# ATSAMRH707F18A register map
Vendor: Microchip Technology; Series: SAMRH707; File version: 0
CPU: CM7 r1p1, little endian, MPU, FPU, double-precision FPU, I-cache, D-cache, ITCM, DTCM, 3 interrupt priority bits, 69 interrupts
Registers are 32-bit, read-write, reset 0x0 unless marked. A register's access mark holds for its fields unless they carry their own. Offsets are from the block's base; [hi:lo] are bit positions; {n}, {i} and the like mark numbered series.

## CoreDebug
Base 0xE000EDF0
0x00 DHCSR — Debug Halting Control and Status Register
  [25] S_RESET_ST ro — Reset Status
  [24] S_RETIRE_ST ro — Retire Status
  [19] S_LOCKUP ro — Locked up status
  [18] S_SLEEP ro — Sleep status
  [17] S_HALT ro — Debug state status
  [16] S_REGRDY ro — Transfer complete flag
  [31:16] DBGKEY wo — Debug key, must write 0xA05F to enable writes
  [5] C_SNAPSTALL — Allow imprecise entry to Debug state
  [3] C_MASKINTS — Mask PendSV, SysTick and external configurable interrupts
  [2] C_STEP — Processor step bit
  [1] C_HALT — Processor halt bit
  [0] C_DEBUGEN — Halting debug enable bit
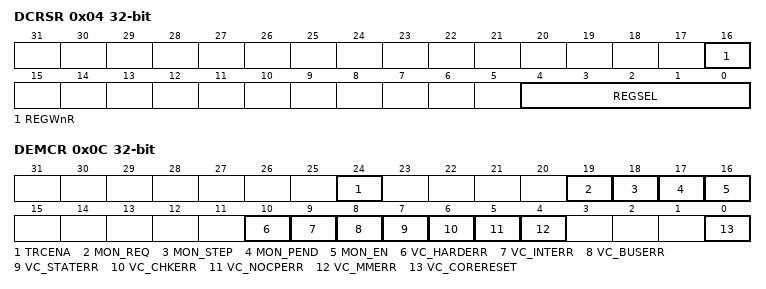
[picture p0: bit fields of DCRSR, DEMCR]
0x04 DCRSR wo — Debug Core Register Selector Register
  [16] REGWnR — Specifies the access type for the transfer
  [4:0] REGSEL — Specifies the Arm core register, special-purpose register, or Floating-point Extension register, to transfer
0x08 DCRDR — Debug Core Register Data Register
  [31:0] DBGTMP — Data temporary cache
0x0C DEMCR — Debug Exception and Monitor Control Register
  [24] TRCENA — Global enable for all DWT and ITM features
  [19] MON_REQ — DebugMonitor semaphore bit
  [18] MON_STEP — Enable DebugMonitor stepping
  [17] MON_PEND — Set DebugMonitor exception pending
  [16] MON_EN — Enable DebugMonitor exception
  [10] VC_HARDERR — HardFault exception catch
  [9] VC_INTERR — Interrupt/exception service error catch
  [8] VC_BUSERR — BusFault exception catch
  [7] VC_STATERR — State error catch
  [6] VC_CHKERR — Checking error catch
  [5] VC_NOCPERR — Coprocessor access error catch
  [4] VC_MMERR — MemManage exception catch
  [0] VC_CORERESET — Reset Vector Catch

## ETM — Embedded Trace Macrocell
Base 0xE0041000
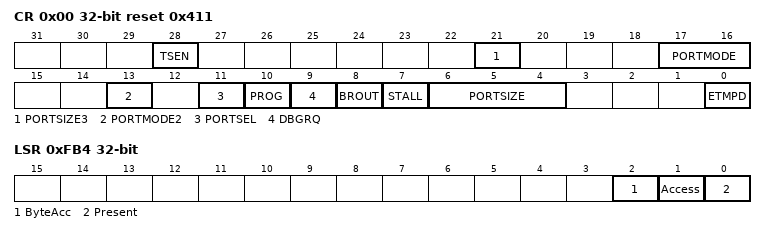
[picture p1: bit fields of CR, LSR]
0x00 CR reset 0x411 — ETM Main Control Register
  [28] TSEN — TimeStamp Enable
  [21] PORTSIZE3 — Port Size bit 3
  [17:16] PORTMODE — Port Mode bits 1:0
  [13] PORTMODE2 — Port Mode bit 2
  [11] PORTSEL — ETM Port Select
  [10] PROG — ETM Programming
  [9] DBGRQ — Debug Request Control
  [8] BROUT — Branch Output
  [7] STALL — Stall Processor
  [6:4] PORTSIZE — Port Size bits 2:0
  [0] ETMPD — ETM Power Down
0x04 CCR ro reset 0x8C802000 — ETM Configuration Code Register
0x08 TRIGGER — ETM Trigger Event Register
0x10 SR — ETM Status Register
0x14 SCR ro reset 0x20D09 — ETM System Configuration Register
0x20 TEEVR — ETM TraceEnable Event Register
0x24 TECR1 — ETM TraceEnable Control 1 Register
0x28 FFLR — ETM FIFO Full Level Register
0x140 CNTRLDVR1 — ETM Free-running Counter Reload Value
0x1E0 SYNCFR ro reset 0x400 — ETM Synchronization Frequency Register
0x1E4 IDR ro reset 0x4114F250 — ETM ID Register
0x1E8 CCER ro reset 0x18541800 — ETM Configuration Code Extension Register
0x1F0 TESSEICR — ETM TraceEnable Start/Stop EmbeddedICE Control Register
0x1F8 TSEVT — ETM TimeStamp Event Register
0x200 TRACEIDR — ETM CoreSight Trace ID Register
0x208 IDR2 ro — ETM ID Register 2
0x314 PDSR ro reset 0x1 — ETM Device Power-Down Status Register
0xEE0 ITMISCIN ro — ETM Integration Test Miscellaneous Inputs
0xEE8 ITTRIGOUT wo — ETM Integration Test Trigger Out
0xEF0 ITATBCTR2 ro — ETM Integration Test ATB Control 2
0xEF8 ITATBCTR0 wo — ETM Integration Test ATB Control 0
0xF00 ITCTRL — ETM Integration Mode Control Register
  [0] INTEGRATION
0xFA0 CLAIMSET write-1-sets — ETM Claim Tag Set Register
0xFA4 CLAIMCLR write-1-clears — ETM Claim Tag Clear Register
0xFB0 LAR wo — ETM Lock Access Register
0xFB4 LSR ro — ETM Lock Status Register
  [2] ByteAcc, [1] Access, [0] Present
0xFB8 AUTHSTATUS ro — ETM Authentication Status Register
0xFCC DEVTYPE ro reset 0x13 — ETM CoreSight Device Type Register
0xFD0 PIDR4 ro reset 0x4 — ETM Peripheral Identification Register #4
{0xFC0+4i} PIDR{i} ro (i=5..7) — ETM Peripheral Identification Register #{i}
0xFE0 PIDR0 ro reset 0x25 — ETM Peripheral Identification Register #0
0xFE4 PIDR1 ro reset 0xB9 — ETM Peripheral Identification Register #1
0xFE8 PIDR2 ro reset 0xB — ETM Peripheral Identification Register #2
0xFEC PIDR3 ro — ETM Peripheral Identification Register #3
0xFF0 CIDR0 ro reset 0xD — ETM Component Identification Register #0
0xFF4 CIDR1 ro reset 0x90 — ETM Component Identification Register #1
0xFF8 CIDR2 ro reset 0x5 — ETM Component Identification Register #2
0xFFC CIDR3 ro reset 0xB1 — ETM Component Identification Register #3

## TPIU — Trace Port Interface Register
Base 0xE0040000
0x00 SSPSR ro — Supported Parallel Port Size Register
0x04 CSPSR — Current Parallel Port Size Register
0x10 ACPR — Asynchronous Clock Prescaler Register
  [12:0] PRESCALER
0xF0 SPPR — Selected Pin Protocol Register
  [1:0] TXMODE
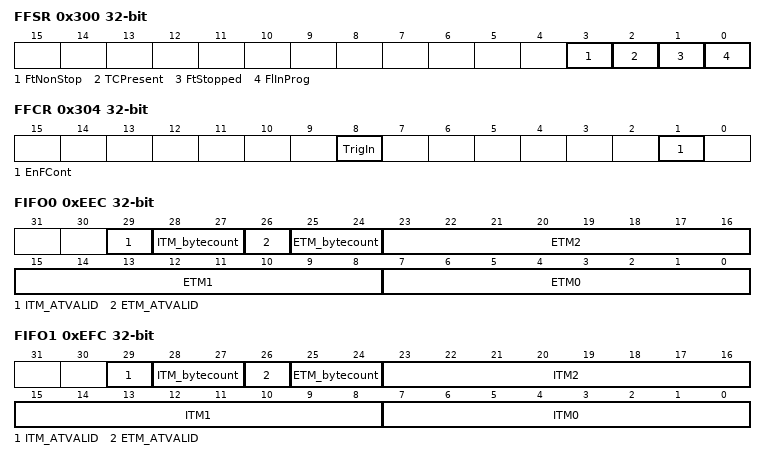
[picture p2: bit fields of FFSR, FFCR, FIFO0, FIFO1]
0x300 FFSR ro — Formatter and Flush Status Register
  [3] FtNonStop, [2] TCPresent, [1] FtStopped, [0] FlInProg
0x304 FFCR — Formatter and Flush Control Register
  [8] TrigIn, [1] EnFCont
0x308 FSCR ro — Formatter Synchronization Counter Register
0xEE8 TRIGGER ro
  [0] TRIGGER
0xEEC FIFO0 ro — Integration ETM Data
  [29] ITM_ATVALID, [28:27] ITM_bytecount, [26] ETM_ATVALID, [25:24] ETM_bytecount, [23:16] ETM2, [15:8] ETM1, [7:0] ETM0
0xEF0 ITATBCTR2 ro
  [0] ATREADY
0xEF8 ITATBCTR0 ro
  [0] ATREADY
0xEFC FIFO1 ro — Integration ITM Data
  [29] ITM_ATVALID, [28:27] ITM_bytecount, [26] ETM_ATVALID, [25:24] ETM_bytecount, [23:16] ITM2, [15:8] ITM1, [7:0] ITM0
0xF00 ITCTRL — Integration Mode Control
  [0] Mode
0xFA0 CLAIMSET write-1-sets — Claim tag set
0xFA4 CLAIMCLR write-1-clears — Claim tag clear
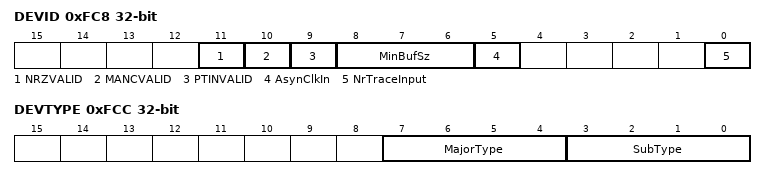
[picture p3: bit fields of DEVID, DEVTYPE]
0xFC8 DEVID ro — TPIU_DEVID
  [11] NRZVALID, [10] MANCVALID, [9] PTINVALID, [8:6] MinBufSz, [5] AsynClkIn, [0] NrTraceInput
0xFCC DEVTYPE ro — TPIU_DEVTYPE
  [7:4] MajorType, [3:0] SubType
